# PIC32MZ0512EFF064 device description
Architecture: MIPS; Family: PIC32MZEF; Series: PIC32MZ
Registers are 32-bit, read-write, no defined reset value unless marked. A register's access mark holds for its fields unless they carry their own. Offsets are from the block's base; [hi:lo] are bit positions; {n}, {i} and the like mark numbered series; 'fields as' and 'values as' point back to an identical list.

## CVR
Instances: CVR 0x1f800e00 in periph_pb1_std
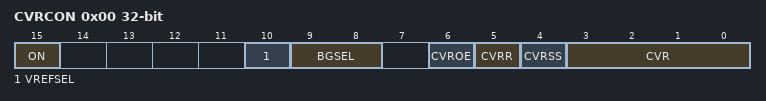
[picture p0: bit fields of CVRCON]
0x00 CVRCON — Comparator Voltage Reference Control Register
  [15] ON — Comparator Voltage Reference On bit
    1=Module is enabled. Setting this bit does not affect other bits in the register.; 0=Module is disabled and does not consume current. Clearing this bit does not affect the other bits in the register.
  [10] VREFSEL
  [9:8] BGSEL
  [6] CVROE — CVrefout Enable bit
    1=Voltage level is output on CVrefout pin; 0=Voltage level is disconnected from CVrefout pin
  [5] CVRR — CVref Range Selection bit
    1=0 to 0.67 CVrsrc; 0=0.25 CVrsrc to 0.75 CVrsrc
  [4] CVRSS — CVref Source Selection bit
    1=Comparator voltage reference source, CVRSRC = (VREF+) - (VREF-); 0=Comparator voltage reference source, CVRSRC = AVDD - AVSS
  [3:0] CVR

## DMT
Instances: DMT 0x1f800a00 in periph_pb1_std
0x00 DMTCON — Deadman Timer Control Register
  [15] ON — Deadman Timer Module Enable bit
    1=Deadman Timer module is enabled; 0=Deadman Timer module is disabled
0x10 DMTPRECLR — Deadman Timer Preclear Register
  [15:8] STEP1 — Preclear Enable bits
    64=Enables the Deadman Timer Preclear (Step 1)
0x20 DMTCLR — Deadman Timer Clear Register
  [7:0] STEP2 — Clear Timer bits
    8=Clears STEP1
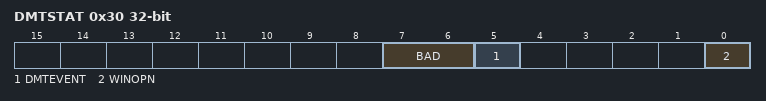
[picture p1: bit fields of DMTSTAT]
0x30 DMTSTAT ro — Deadman Timer Status Register
  [7:6] BAD
  [5] DMTEVENT — Deadman Timer Event bit
    1=Deadman timer event was detected (counter expired or bad STEP1 or STEP2 value was entered prior to counter increment); 0=Deadman timer even was not detected
  [0] WINOPN — Deadman Timer Clear Window bit
    1=Deadman timer clear window is open; 0=Deadman timer clear window is not open
0x40 DMTCNT ro — Deadman Timer Count Register
  [31:0] COUNTER
0x60 DMTPSCNT ro — Post Status Configure DMT Count Status Register
  [31:0] PSCNT
0x70 DMTPSINTV ro — Post Status Configure DMT Interval Status Register
  [31:0] PSINTV
Value list DMTSTAT__BAD2: 64=Incorrect STEP2 value was detected; 0=Incorrect STEP2 value was not detected
Value list DMTSTAT__BAD1: 128=Incorrect STEP1 value or out of sequence write to STEP2 was detected; 0=Incorrect STEP1 value was not detected

## GPIO
Instances: GPIO 0x1f860100 in periph_pb4_std
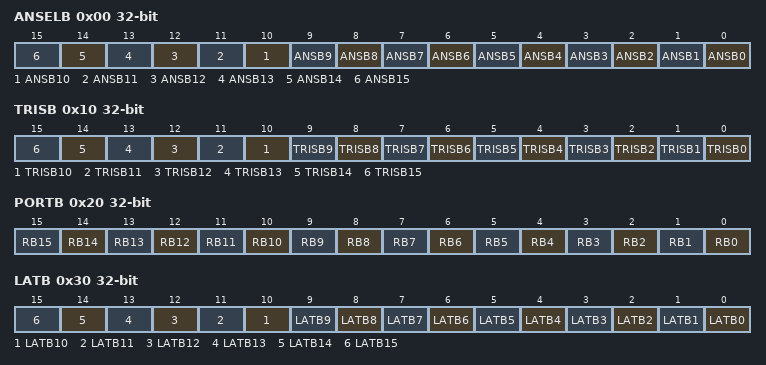
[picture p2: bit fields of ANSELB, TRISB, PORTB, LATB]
0x00 ANSELB
  [n] ANSB{n} (n=0..15)
0x10 TRISB
  [n] TRISB{n} (n=0..15)
0x20 PORTB
  [n] RB{n} (n=0..15)
0x30 LATB
  [n] LATB{n} (n=0..15)
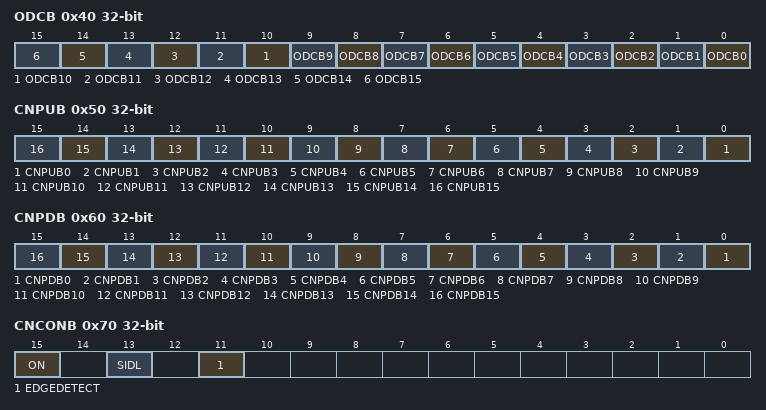
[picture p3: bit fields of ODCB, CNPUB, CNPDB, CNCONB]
0x40 ODCB
  [n] ODCB{n} (n=0..15)
0x50 CNPUB
  [n] CNPUB{n} (n=0..15)
0x60 CNPDB
  [n] CNPDB{n} (n=0..15)
0x70 CNCONB — Change Notice control for PORTx Register
  [15] ON — Change Notice Control ON bit
    1=CN is enabled; 0=CN is disabled
  [13] SIDL
  [11] EDGEDETECT — Change Notification Style bit
    1=Edge Style. Detect edge transitions (CNFx used for CN Event).; 0=Mismatch Style. Detect change from last PORTx read (CNSTATx used for CN Event).
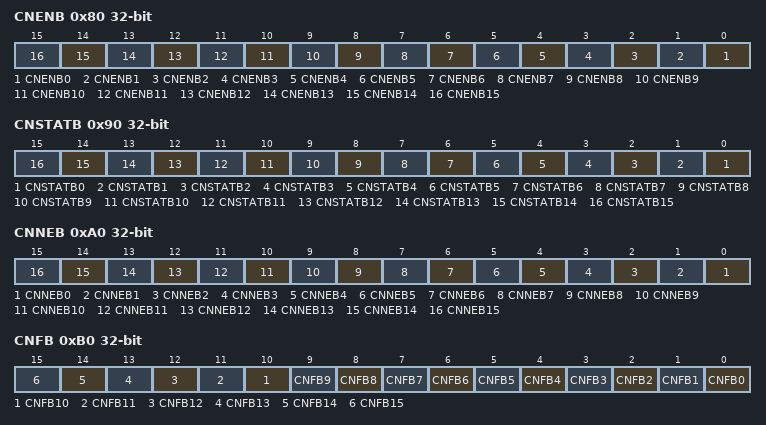
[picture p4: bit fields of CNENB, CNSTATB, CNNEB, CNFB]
0x80 CNENB
  [n] CNENB{n} (n=0..15)
0x90 CNSTATB
  [n] CNSTATB{n} (n=0..15)
0xA0 CNNEB
  [n] CNNEB{n} (n=0..15)
0xB0 CNFB
  [n] CNFB{n} (n=0..15)
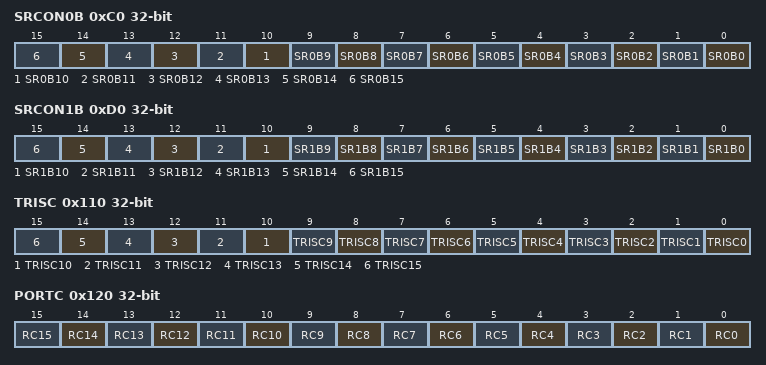
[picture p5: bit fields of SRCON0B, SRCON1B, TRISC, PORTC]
0xC0 SRCON0B
  [n] SR0B{n} (n=0..15)
0xD0 SRCON1B
  [n] SR1B{n} (n=0..15)
0x110 TRISC
  [n] TRISC{n} (n=0..15)
0x120 PORTC
  [n] RC{n} (n=0..15)
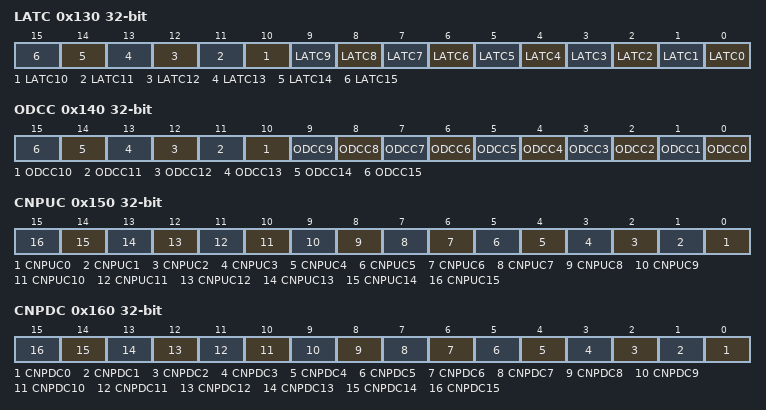
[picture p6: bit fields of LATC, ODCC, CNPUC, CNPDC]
0x130 LATC
  [n] LATC{n} (n=0..15)
0x140 ODCC
  [n] ODCC{n} (n=0..15)
0x150 CNPUC
  [n] CNPUC{n} (n=0..15)
0x160 CNPDC
  [n] CNPDC{n} (n=0..15)
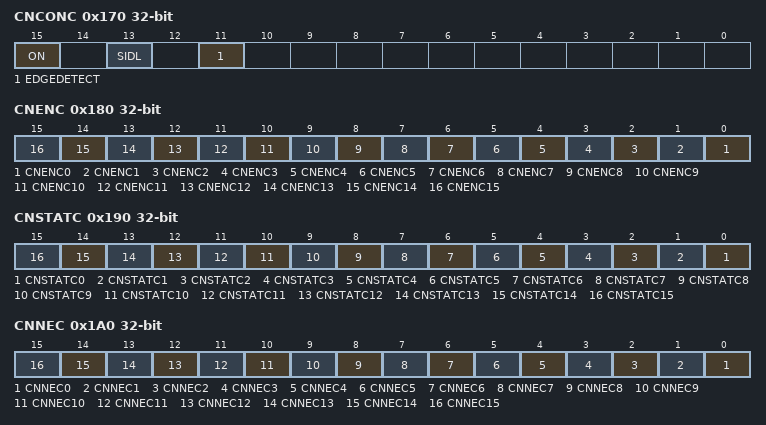
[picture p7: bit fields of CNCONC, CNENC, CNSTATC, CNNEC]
0x170 CNCONC — Change Notice control for PORTx Register
  fields as CNCONB
0x180 CNENC
  [n] CNENC{n} (n=0..15)
0x190 CNSTATC
  [n] CNSTATC{n} (n=0..15)
0x1A0 CNNEC
  [n] CNNEC{n} (n=0..15)
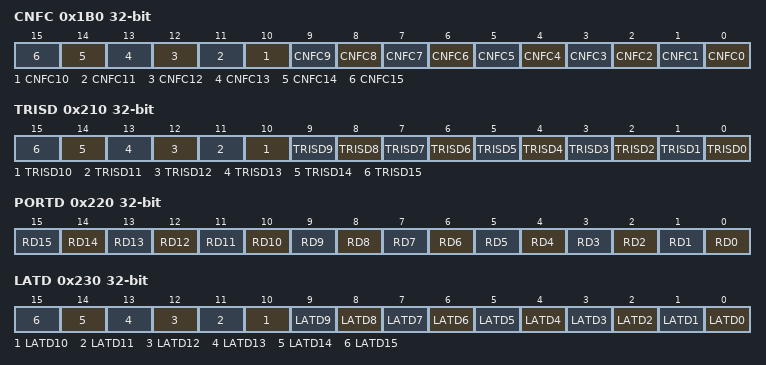
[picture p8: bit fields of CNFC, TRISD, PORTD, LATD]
0x1B0 CNFC
  [n] CNFC{n} (n=0..15)
0x210 TRISD
  [n] TRISD{n} (n=0..15)
0x220 PORTD
  [n] RD{n} (n=0..15)
0x230 LATD
  [n] LATD{n} (n=0..15)
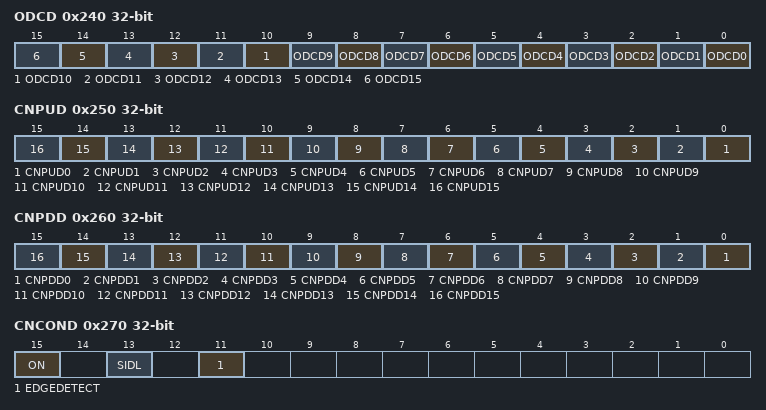
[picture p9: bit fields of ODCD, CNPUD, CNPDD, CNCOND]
0x240 ODCD
  [n] ODCD{n} (n=0..15)
0x250 CNPUD
  [n] CNPUD{n} (n=0..15)
0x260 CNPDD
  [n] CNPDD{n} (n=0..15)
0x270 CNCOND — Change Notice control for PORTx Register
  fields as CNCONB
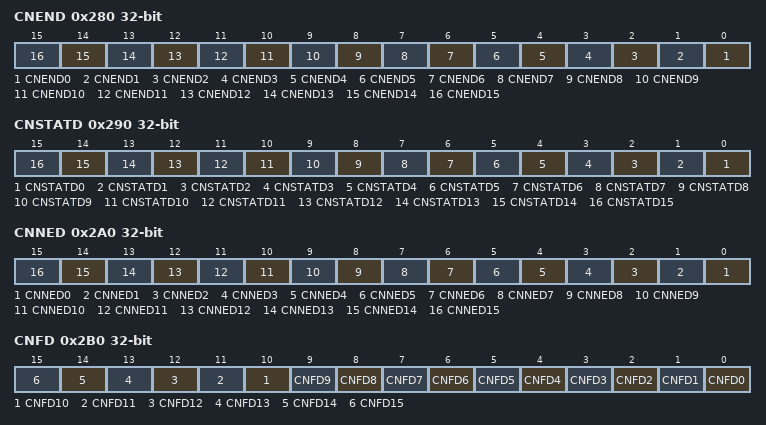
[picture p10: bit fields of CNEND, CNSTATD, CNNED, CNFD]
0x280 CNEND
  [n] CNEND{n} (n=0..15)
0x290 CNSTATD
  [n] CNSTATD{n} (n=0..15)
0x2A0 CNNED
  [n] CNNED{n} (n=0..15)
0x2B0 CNFD
  [n] CNFD{n} (n=0..15)
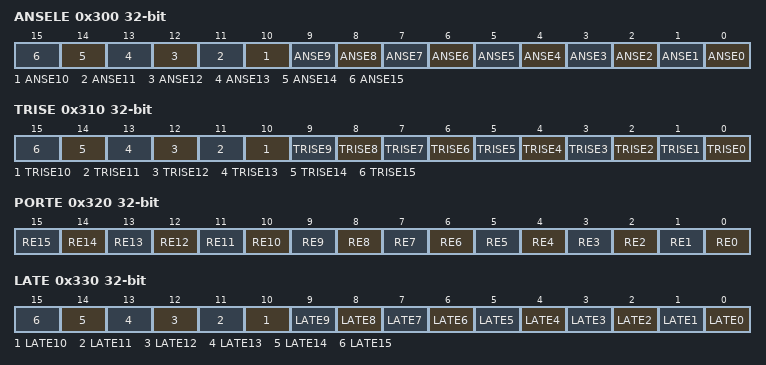
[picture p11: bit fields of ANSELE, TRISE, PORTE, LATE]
0x300 ANSELE
  [n] ANSE{n} (n=0..15)
0x310 TRISE
  [n] TRISE{n} (n=0..15)
0x320 PORTE
  [n] RE{n} (n=0..15)
0x330 LATE
  [n] LATE{n} (n=0..15)
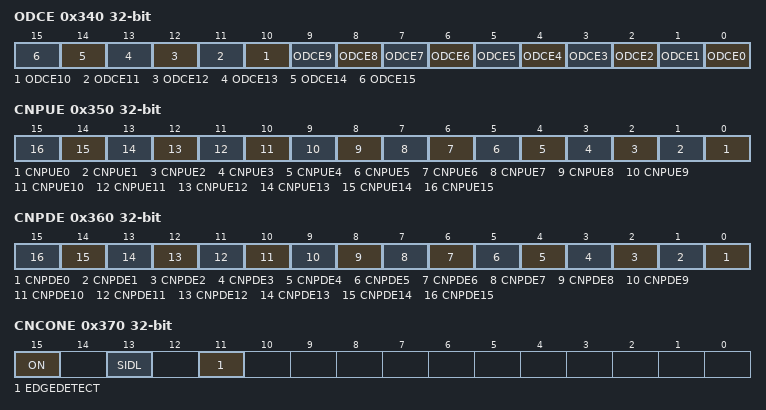
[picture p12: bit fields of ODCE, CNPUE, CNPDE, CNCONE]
0x340 ODCE
  [n] ODCE{n} (n=0..15)
0x350 CNPUE
  [n] CNPUE{n} (n=0..15)
0x360 CNPDE
  [n] CNPDE{n} (n=0..15)
0x370 CNCONE — Change Notice control for PORTx Register
  fields as CNCONB
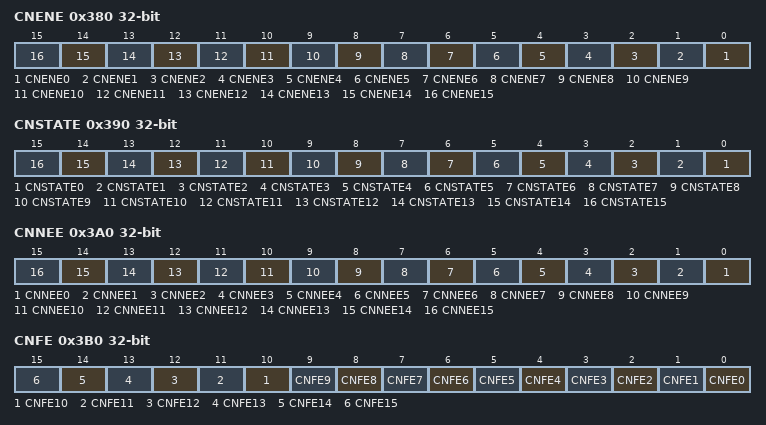
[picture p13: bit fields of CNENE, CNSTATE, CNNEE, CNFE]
0x380 CNENE
  [n] CNENE{n} (n=0..15)
0x390 CNSTATE
  [n] CNSTATE{n} (n=0..15)
0x3A0 CNNEE
  [n] CNNEE{n} (n=0..15)
0x3B0 CNFE
  [n] CNFE{n} (n=0..15)
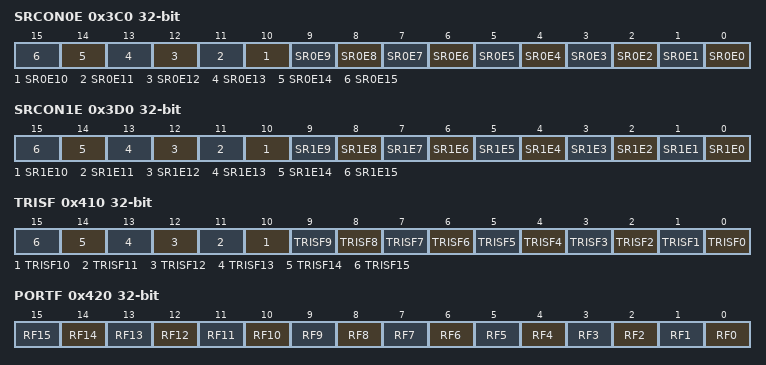
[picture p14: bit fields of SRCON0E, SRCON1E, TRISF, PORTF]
0x3C0 SRCON0E
  [n] SR0E{n} (n=0..15)
0x3D0 SRCON1E
  [n] SR1E{n} (n=0..15)
0x410 TRISF
  [n] TRISF{n} (n=0..15)
0x420 PORTF
  [n] RF{n} (n=0..15)
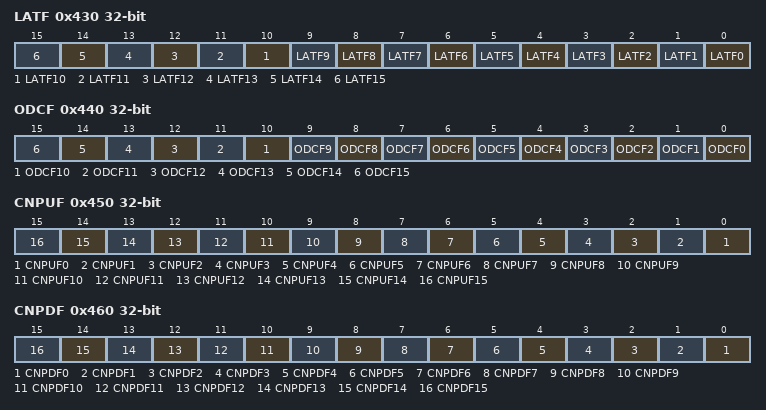
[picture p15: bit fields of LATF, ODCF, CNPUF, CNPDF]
0x430 LATF
  [n] LATF{n} (n=0..15)
0x440 ODCF
  [n] ODCF{n} (n=0..15)
0x450 CNPUF
  [n] CNPUF{n} (n=0..15)
0x460 CNPDF
  [n] CNPDF{n} (n=0..15)
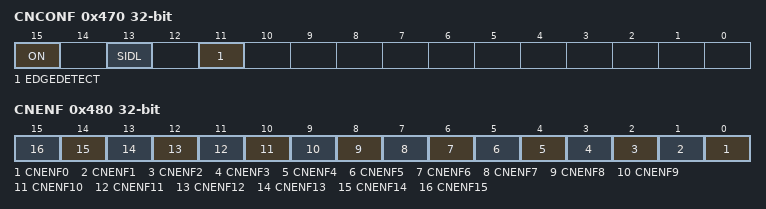
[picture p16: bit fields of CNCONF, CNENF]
0x470 CNCONF — Change Notice control for PORTx Register
  fields as CNCONB
0x480 CNENF
  [n] CNENF{n} (n=0..15)
0x490 CNSTATF
  [n] CNSTATF{n} (n=0..15)
0x4A0 CNNEF
  [n] CNNEF{n} (n=0..15)
0x4B0 CNFF
  [n] CNFF{n} (n=0..15)
0x4C0 SRCON0F
  [n] SR0F{n} (n=0..15)
0x4D0 SRCON1F
  [n] SR1F{n} (n=0..15)
0x500 ANSELG
  [n] ANSG{n} (n=0..15)
0x510 TRISG
  [n] TRISG{n} (n=0..15)
0x520 PORTG
  [n] RG{n} (n=0..15)
0x530 LATG
  [n] LATG{n} (n=0..15)
0x540 ODCG
  [n] ODCG{n} (n=0..15)
0x550 CNPUG
  [n] CNPUG{n} (n=0..15)
0x560 CNPDG
  [n] CNPDG{n} (n=0..15)
0x570 CNCONG — Change Notice control for PORTx Register
  fields as CNCONB
0x580 CNENG
  [n] CNENG{n} (n=0..15)
0x590 CNSTATG
  [n] CNSTATG{n} (n=0..15)
0x5A0 CNNEG
  [n] CNNEG{n} (n=0..15)
0x5B0 CNFG
  [n] CNFG{n} (n=0..15)
0x5C0 SRCON0G
  [n] SR0G{n} (n=0..15)
0x5D0 SRCON1G
  [n] SR1G{n} (n=0..15)

## Notices in the file
Copyright (c) 2017 Microchip Technology Inc.
SPDX-License-Identifier: Apache-2.0
Licensed under the Apache License, Version 2.0 (the "License");
you may not use this file except in compliance with the License.
You may obtain a copy of the License at
http://www.apache.org/licenses/LICENSE-2.0
Unless required by applicable law or agreed to in writing, software
distributed under the License is distributed on an "AS IS" BASIS,
WITHOUT WARRANTIES OR CONDITIONS OF ANY KIND, either express or implied.
See the License for the specific language governing permissions and
limitations under the License.
